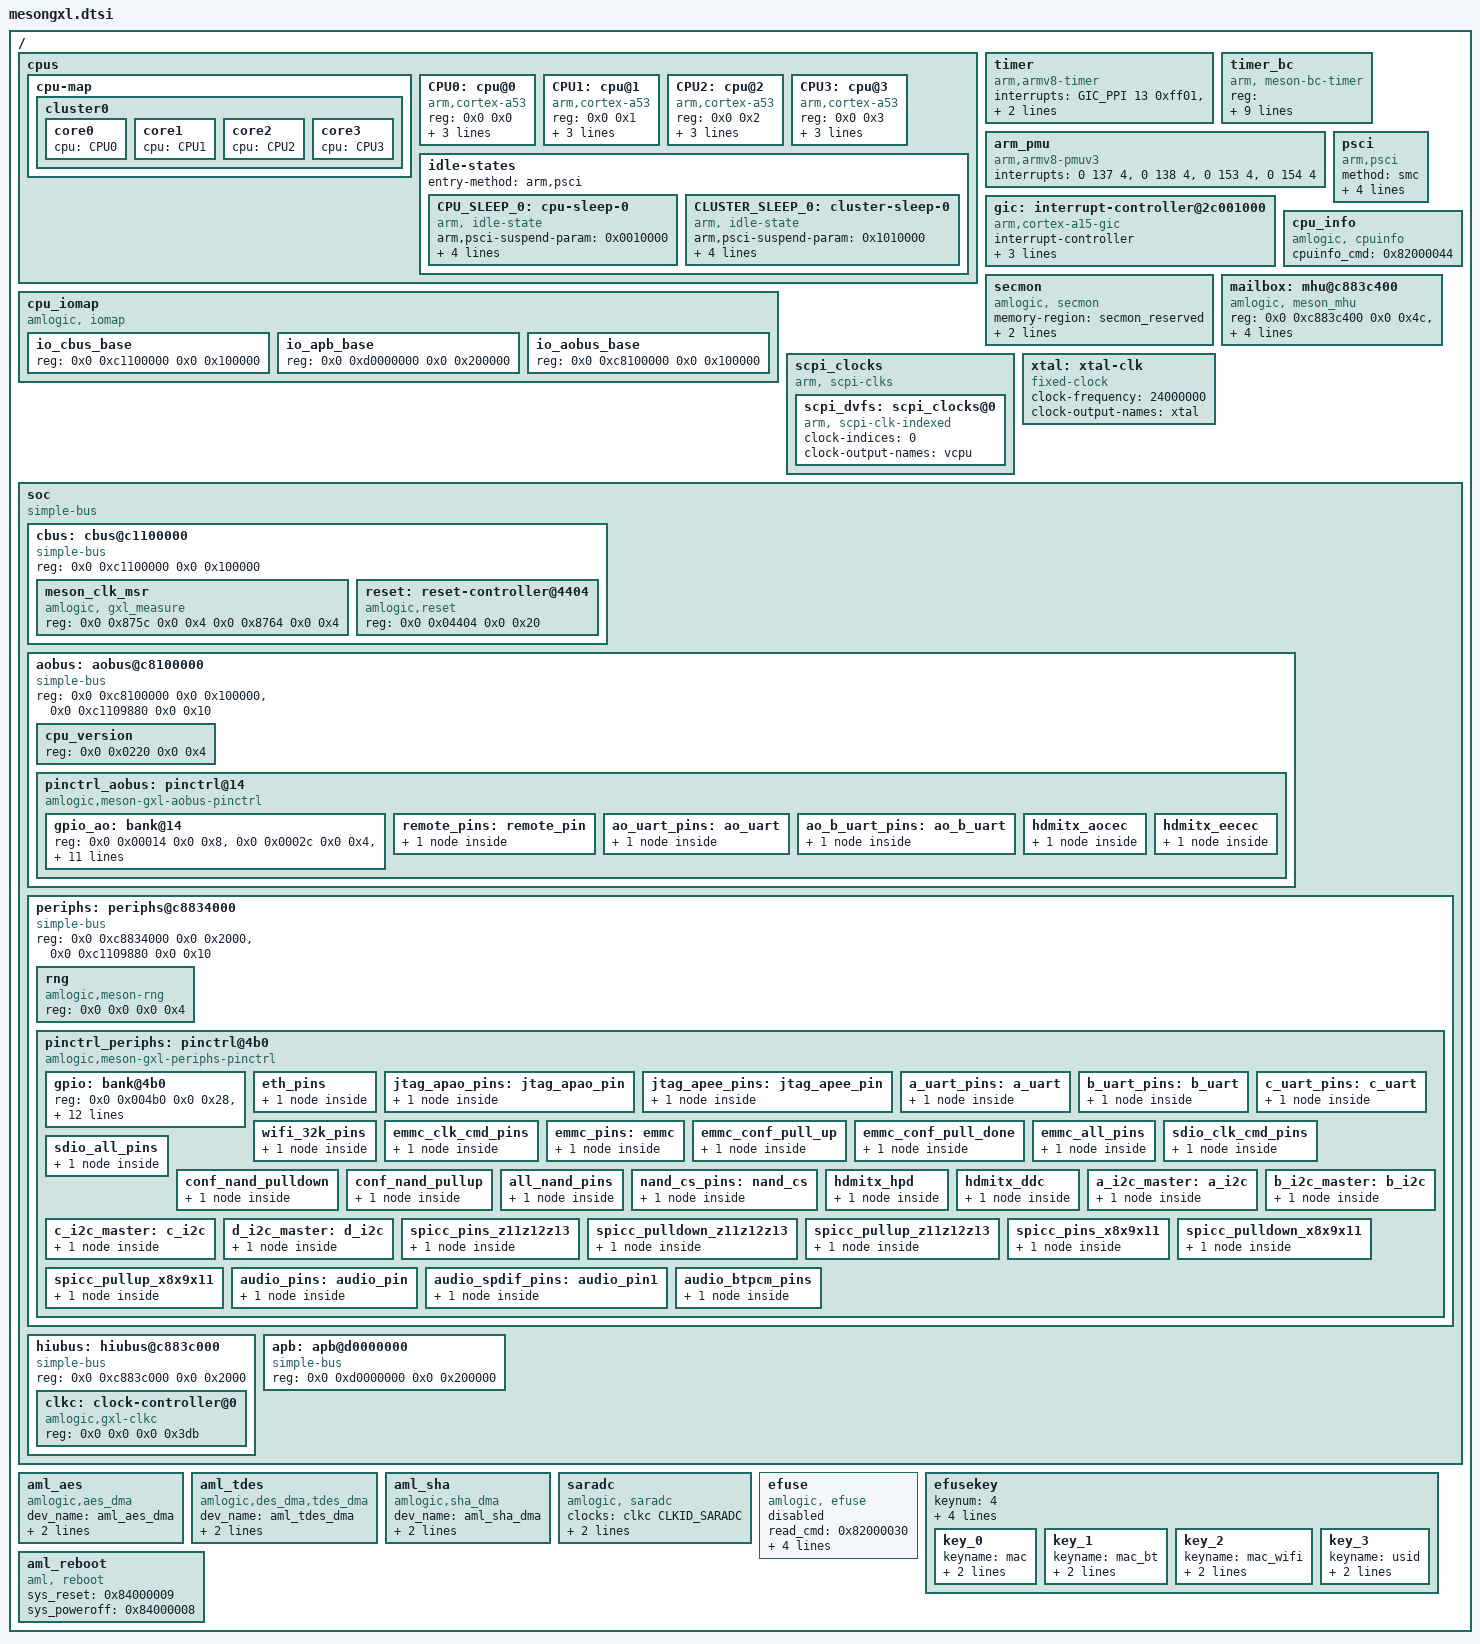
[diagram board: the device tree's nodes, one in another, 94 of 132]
/*
 * arch/arm64/boot/dts/amlogic/mesongxl.dtsi
 *
 * Copyright (C) 2017 Amlogic, Inc. All rights reserved.
 *
 * This program is free software; you can redistribute it and/or modify
 * it under the terms of the GNU General Public License as published by
 * the Free Software Foundation; either version 2 of the License, or
 * (at your option) any later version.
 *
 * This program is distributed in the hope that it will be useful, but WITHOUT
 * ANY WARRANTY; without even the implied warranty of MERCHANTABILITY or
 * FITNESS FOR A PARTICULAR PURPOSE.  See the GNU General Public License for
 * more details.
 *
 */

#include <dt-bindings/interrupt-controller/arm-gic.h>
#include <dt-bindings/reset/amlogic,gxl-reset.h>
#include <dt-bindings/clock/amlogic,gxl-clkc.h>
/ {
	cpus:cpus {
		#address-cells = <2>;
		#size-cells = <0>;

		cpu-map {
			cluster0:cluster0 {
				#cooling-cells = <2>; /* min followed by max */
				core0 {
					cpu = <&CPU0>;
				};
				core1 {
					cpu = <&CPU1>;
				};
				core2 {
					cpu = <&CPU2>;
				};
				core3 {
					cpu = <&CPU3>;
				};
			};
		};
		CPU0:cpu@0 {
			device_type = "cpu";
			compatible = "arm,cortex-a53","arm,armv8";
			reg = <0x0 0x0>;
			enable-method = "psci";
			clocks = <&scpi_dvfs 0>;
			clock-names = "cpu-cluster.0";
			cpu-idle-states = <&CPU_SLEEP_0 &CLUSTER_SLEEP_0>;
		};

		CPU1:cpu@1 {
			device_type = "cpu";
			compatible = "arm,cortex-a53","arm,armv8";
			reg = <0x0 0x1>;
			enable-method = "psci";
			clocks = <&scpi_dvfs 0>;
			clock-names = "cpu-cluster.0";
			cpu-idle-states = <&CPU_SLEEP_0 &CLUSTER_SLEEP_0>;
		};
		CPU2:cpu@2 {
			device_type = "cpu";
			compatible = "arm,cortex-a53","arm,armv8";
			reg = <0x0 0x2>;
			enable-method = "psci";
			clocks = <&scpi_dvfs 0>;
			clock-names = "cpu-cluster.0";
			cpu-idle-states = <&CPU_SLEEP_0 &CLUSTER_SLEEP_0>;
		};

		CPU3:cpu@3 {
			device_type = "cpu";
			compatible = "arm,cortex-a53","arm,armv8";
			reg = <0x0 0x3>;
			enable-method = "psci";
			clocks = <&scpi_dvfs 0>;
			clock-names = "cpu-cluster.0";
			cpu-idle-states = <&CPU_SLEEP_0 &CLUSTER_SLEEP_0>;
		};


		idle-states {
			entry-method = "arm,psci";

			CPU_SLEEP_0: cpu-sleep-0 {
				compatible = "arm, idle-state";
				arm,psci-suspend-param = <0x0010000>;
				local-timer-stop;
				entry-latency-us = <3000>;
				exit-latency-us = <3000>;
				min-residency-us = <8000>;
			};

			CLUSTER_SLEEP_0: cluster-sleep-0 {
				compatible = "arm, idle-state";
				arm,psci-suspend-param = <0x1010000>;
				local-timer-stop;
				entry-latency-us = <3000>;
				exit-latency-us = <3000>;
				min-residency-us = <15000>;
			};
		};
	};

	timer {
		compatible = "arm,armv8-timer";
		interrupts = <GIC_PPI 13 0xff01>,
				<GIC_PPI 14 0xff01>,
				<GIC_PPI 11 0xff01>,
				<GIC_PPI 10 0xff01>;
	};
	timer_bc {
		compatible = "arm, meson-bc-timer";
		reg=   <0x0 0xc1109990 0x0 0x4 0x0 0xc1109994 0x0 0x4>;
		timer_name = "Meson TimerF";
		clockevent-rating=<300>;
		clockevent-shift=<20>;
		clockevent-features=<0x23>;
		interrupts = <0 60 1>;
		bit_enable=<16>;
		bit_mode=<12>;
		bit_resolution=<0>;
	};
	arm_pmu {
		compatible = "arm,armv8-pmuv3";
		interrupts = <0 137 4>,
			     <0 138 4>,
			     <0 153 4>,
			     <0 154 4>;
	};

	gic: interrupt-controller@2c001000 {
		compatible = "arm,cortex-a15-gic", "arm,cortex-a9-gic";
		#interrupt-cells = <3>;
		#address-cells = <0>;
		interrupt-controller;
		reg = <0x0 0xc4301000 0 0x1000>,
		      <0x0 0xc4302000 0 0x0100>;
		interrupts = <GIC_PPI 9 0xf04>;
	};

	psci {
		compatible = "arm,psci";
		method = "smc";
		cpu_suspend = <0xC4000001>;
		cpu_off = <0x84000002>;
		cpu_on = <0xC4000003>;
		migrate = <0xC4000005>;
	};

	secmon {
		compatible = "amlogic, secmon";
		memory-region = <&secmon_reserved>;
		in_base_func = <0x82000020>;
		out_base_func = <0x82000021>;
	};

	cpu_iomap{
		compatible = "amlogic, iomap";
		#address-cells=<2>;
		#size-cells=<2>;
		ranges;
		io_cbus_base{
			reg = <0x0 0xc1100000 0x0 0x100000>;
		};
		io_apb_base{
			reg = <0x0 0xd0000000 0x0 0x200000>;
		};
		io_aobus_base{
			reg = <0x0 0xc8100000 0x0 0x100000>;
		};
	};

	cpu_info{
		compatible = "amlogic, cpuinfo";
		cpuinfo_cmd = <0x82000044>;
		status = "okay";
	};

	mailbox: mhu@c883c400 {
		compatible = "amlogic, meson_mhu";
		reg = <0x0 0xc883c400 0x0 0x4c>,   /* MHU registers */
		      <0x0 0xc8013000 0x0 0x800>;   /* Payload area */
		interrupts = <0 209 1>,   /* low priority interrupt */
			     <0 210 1>;   /* high priority interrupt */
		#mbox-cells = <1>;
		mbox-names = "cpu_to_scp_low", "cpu_to_scp_high";
		mboxes = <&mailbox 0 &mailbox 1>;
	};

	scpi_clocks {
		compatible = "arm, scpi-clks";

		scpi_dvfs: scpi_clocks@0 {
			compatible = "arm, scpi-clk-indexed";
			#clock-cells = <1>;
			clock-indices = <0>;
			clock-output-names = "vcpu";
		};

	};

	xtal: xtal-clk {
		compatible = "fixed-clock";
		clock-frequency = <24000000>;
		clock-output-names = "xtal";
		#clock-cells = <0>;
	};

	soc {
		compatible = "simple-bus";
		#address-cells = <2>;
		#size-cells = <2>;
		ranges;

		cbus: cbus@c1100000 {
			compatible = "simple-bus";
			reg = <0x0 0xc1100000 0x0 0x100000>;
			#address-cells = <2>;
			#size-cells = <2>;
			ranges = <0x0 0x0 0x0 0xc1100000 0x0 0x100000>;

			meson_clk_msr{
				compatible = "amlogic, gxl_measure";
				reg = <0x0 0x875c 0x0 0x4
					0x0 0x8764 0x0 0x4>;
			};
		};

		aobus: aobus@c8100000 {
			compatible = "simple-bus";
			reg = <0x0 0xc8100000 0x0 0x100000>,
				<0x0 0xc1109880 0x0 0x10>;
			#address-cells = <2>;
			#size-cells = <2>;
			ranges = <0x0 0x0 0x0 0xc8100000 0x0 0x100000>;

			cpu_version{
				reg=<0x0 0x0220 0x0 0x4>;
			};
		};

		periphs: periphs@c8834000 {
			compatible = "simple-bus";
			reg = <0x0 0xc8834000 0x0 0x2000>,
				<0x0 0xc1109880 0x0 0x10>;
			#address-cells = <2>;
			#size-cells = <2>;
			ranges = <0x0 0x0 0x0 0xc8834000 0x0 0x2000>;
		};

		hiubus: hiubus@c883c000 {
			compatible = "simple-bus";
			reg = <0x0 0xc883c000 0x0 0x2000>;
			#address-cells = <2>;
			#size-cells = <2>;
			ranges = <0x0 0x0 0x0 0xc883c000 0x0 0x2000>;

			clkc: clock-controller@0 {
				compatible = "amlogic,gxl-clkc";
				#clock-cells = <1>;
				reg = <0x0 0x0 0x0 0x3db>;
			};
		};

		apb: apb@d0000000 {
			compatible = "simple-bus";
			reg = <0x0 0xd0000000 0x0 0x200000>;
			#address-cells = <2>;
			#size-cells = <2>;
			ranges = <0x0 0x0 0x0 0xd0000000 0x0 0x200000>;
		};
	}; /* end of soc */
}; /* end of root */

&aobus {
	pinctrl_aobus: pinctrl@14 {
		compatible = "amlogic,meson-gxl-aobus-pinctrl";
		#address-cells = <2>;
		#size-cells = <2>;
		ranges;

		gpio_ao: bank@14 {
			reg = <0x0 0x00014 0x0 0x8>,
			      <0x0 0x0002c 0x0 0x4>,
			      <0x0 0x00024 0x0 0x8>;
			interrupts = <GIC_SPI 64 IRQ_TYPE_EDGE_RISING>,
				<GIC_SPI 65 IRQ_TYPE_EDGE_RISING>,
				<GIC_SPI 66 IRQ_TYPE_EDGE_RISING>,
				<GIC_SPI 67 IRQ_TYPE_EDGE_RISING>,
				<GIC_SPI 68 IRQ_TYPE_EDGE_RISING>,
				<GIC_SPI 69 IRQ_TYPE_EDGE_RISING>,
				<GIC_SPI 70 IRQ_TYPE_EDGE_RISING>,
				<GIC_SPI 71 IRQ_TYPE_EDGE_RISING>;
			reg-names = "mux", "pull", "gpio";
			gpio-controller;
			#gpio-cells = <2>;
			interrupt-controller;
			#interrupt-cells = <2>;
		};

		remote_pins:remote_pin {
			mux {
				groups = "remote_input";
				function = "remote";
			};
		};

		ao_uart_pins:ao_uart {
			mux {
				groups = "uart_tx_ao_a_0",
					"uart_rx_ao_a_0";
				function = "uart_ao";
			};
		};

		ao_b_uart_pins:ao_b_uart {
			mux {
				groups = "uart_tx_ao_b_0",
						"uart_rx_ao_b_0";
				function = "uart_ao_b";
			};
		};

		hdmitx_aocec: hdmitx_aocec {
			mux {
				groups = "ao_cec";
				function = "ao_cec";
			};
		};

		hdmitx_eecec: hdmitx_eecec {
			mux {
				groups = "ee_cec";
				function = "ee_cec";
			};
		};
	}; /* end of pinctrl_aobus*/

}; /* end of aobus*/

&periphs {
	rng {
		compatible = "amlogic,meson-rng";
		reg = <0x0 0x0 0x0 0x4>;
	};

	pinctrl_periphs: pinctrl@4b0 {
		compatible = "amlogic,meson-gxl-periphs-pinctrl";
		#address-cells = <2>;
		#size-cells = <2>;
		ranges;

		gpio: bank@4b0 {
			reg = <0x0 0x004b0 0x0 0x28>,
			      <0x0 0x004e8 0x0 0x14>,
			      <0x0 0x00120 0x0 0x14>,
			      <0x0 0x00430 0x0 0x40>;
			interrupts = <GIC_SPI 64 IRQ_TYPE_EDGE_RISING>,
				<GIC_SPI 65 IRQ_TYPE_EDGE_RISING>,
				<GIC_SPI 66 IRQ_TYPE_EDGE_RISING>,
				<GIC_SPI 67 IRQ_TYPE_EDGE_RISING>,
				<GIC_SPI 68 IRQ_TYPE_EDGE_RISING>,
				<GIC_SPI 69 IRQ_TYPE_EDGE_RISING>,
				<GIC_SPI 70 IRQ_TYPE_EDGE_RISING>,
				<GIC_SPI 71 IRQ_TYPE_EDGE_RISING>;
			reg-names = "mux", "pull",
				"pull-enable", "gpio";
			gpio-controller;
			#gpio-cells = <2>;
			interrupt-controller;
			#interrupt-cells = <2>;
		};

		eth_pins:eth_pins {
			mux {
				groups = "eth_mdio",
					"eth_mdc",
					"eth_clk_rx_clk",
					"eth_rx_dv",
					"eth_rxd0",
					"eth_rxd1",
					"eth_rxd2",
					"eth_rxd3",
					"eth_rgmii_tx_clk",
					"eth_tx_en",
					"eth_txd0",
					"eth_txd1",
					"eth_txd2",
					"eth_txd3";
				function = "eth";
			};
		};

		jtag_apao_pins:jtag_apao_pin {
			mux {
				groups = "jtag_tdi_0",
					"jtag_tdo_0",
					"jtag_clk_0",
					"jtag_tms_0";
				function = "jtag";
			};
		};

		jtag_apee_pins:jtag_apee_pin {
			mux {
				groups ="jtag_tdi_1",
					"jtag_tdo_1",
					"jtag_clk_1",
					"jtag_tms_1";
				function = "jtag";
			};
		};

		a_uart_pins:a_uart {
			mux {
				groups = "uart_tx_a",
					"uart_rx_a";
				function = "uart_a";
			};
		};

		b_uart_pins:b_uart {
			mux {
				groups = "uart_tx_b",
					"uart_rx_b";
				function = "uart_b";
			};
		};

		c_uart_pins:c_uart {
			mux {
				groups = "uart_tx_c",
					"uart_rx_c";
				function = "uart_c";
			};
		};

		wifi_32k_pins:wifi_32k_pins {
			mux {
				groups ="pwm_e";
				function = "pwm_e";
			};
		};

/*
 * sd_clk_cmd_pins:sd_clk_cmd_pins{
 * };
 * sd_all_pins:sd_all_pins {
 *  };
 * sd_1bit_pins:sd_1bit_pins{
 *  };
 *  sd_clk_cmd_uart_pins:sd_clk_cmd_uart_pins {
 * };
 * sd_1bit_uart_pins:sd_1bit_uart_pins {
 *  };
 * sd_to_ao_uart_pins:sd_to_ao_uart_pins {
 *  };
 * ao_to_sd_uart_pins:ao_to_sd_uart_pins {
 * };
 * sd_to_ao_jtag_pins:sd_to_ao_jtag_pins{
 * };
 */

		emmc_clk_cmd_pins:emmc_clk_cmd_pins {
			mux {
				groups = "emmc_cmd",
					"emmc_clk";
				function = "emmc";
				bias-pull-up;
				input-enable;
			};
		};

		emmc_pins: emmc {
			mux {
				groups = "emmc_nand_d07",
					"emmc_cmd",
					"emmc_clk";
				function = "emmc";
			};
		};

		emmc_conf_pull_up:emmc_conf_pull_up {
			mux {
				groups = "emmc_nand_d07",
					"emmc_clk",
					"emmc_cmd";
				function = "emmc";
				bias-pull-up;
			};
		};

		emmc_conf_pull_done:emmc_conf_pull_done {
			mux {
				groups = "emmc_ds";
				function = "emmc";
				bias-pull-down;
			};
		};

		emmc_all_pins:emmc_all_pins {
			mux {
				groups = "emmc_nand_d07",
					"emmc_clk",
					"emmc_cmd";
				function = "emmc";
				input-enable;
			};
		};

		sdio_clk_cmd_pins:sdio_clk_cmd_pins {
			mux {
				groups = "sdio_clk",
					"sdio_cmd";
				function = "sdio";
				input-enable;
				bias-pull-up;
			};
		};

		sdio_all_pins:sdio_all_pins {
			mux {
				groups = "sdio_d0",
					"sdio_d1",
					"sdio_d2",
					"sdio_d3",
					"sdio_clk",
					"sdio_cmd";
				function = "sdio";
				input-enable;
				bias-pull-up;
			};
		};

		conf_nand_pulldown: conf_nand_pulldown {
			mux {
				groups = "emmc_nand_d07",
					"emmc_ds";
				function = "emmc";
				bias-pull-down;
			};
		};

		conf_nand_pullup: conf_nand_pullup {
			mux {
				groups = "emmc_clk",
					"emmc_cmd";
				function = "emmc";
				bias-pull-up;
			};
		};

		all_nand_pins: all_nand_pins {
			mux {
				groups = "emmc_nand_d07",
					"nand_ce0",
					"nand_ce1",
					"nand_rb0",
					"nand_ale",
					"nand_cle",
					"nand_wen_clk",
					"nand_ren_wr",
					"nand_dqs";
				function = "nand";
				input-enable;
			};
		};

		nand_cs_pins: nand_cs {
			mux {
				groups = "nand_ce0",
					"nand_ce1";
				function = "nand";
			};
		};

		hdmitx_hpd: hdmitx_hpd {
			mux {
				groups = "hdmi_hpd";
				function = "hdmi_hpd";
			};
		};

		hdmitx_ddc: hdmitx_ddc {
			mux {
				groups = "hdmi_sda",
					"hdmi_scl";
				function = "hdmi_ddc";
			};
		};

		a_i2c_master:a_i2c {
			mux {
				groups = "i2c_sda_a",
					"i2c_sda_a";
				function = "i2c_a";
			};
		};

		b_i2c_master:b_i2c {
			mux {
				groups = "i2c_sda_b",
					"i2c_sda_b";
				function = "i2c_b";
			};
		};

		c_i2c_master:c_i2c {
			mux {
				groups = "i2c_sda_c",
					"i2c_sda_c";
				function = "i2c_c";
			};
		};

		d_i2c_master:d_i2c {
			mux {
			groups = "i2c_sda_d",
				"i2c_sda_d";
			function = "i2c_d";
			};
		};

		spicc_pins_z11z12z13: spicc_pins_z11z12z13 {
			mux {
				groups = "spi_sclk_0",
					"spi_miso_0",
					"spi_mosi_0";
				function = "spi";
			};
		};

		spicc_pulldown_z11z12z13: spicc_pulldown_z11z12z13 {
			mux {
				groups = "spi_sclk_0",
					"spi_miso_0",
					"spi_mosi_0";
				function = "spi";
			};
		};

		spicc_pullup_z11z12z13: spicc_pullup_z11z12z13 {
			mux {
				groups = "spi_sclk_0",
					"spi_miso_0",
					"spi_mosi_0";
				function = "spi";
			};
		};

		spicc_pins_x8x9x11: spicc_pins_x8x9x11 {
			mux {
				groups = "spi_sclk_1",
					"spi_miso_1",
					"spi_mosi_1";
				function = "spi";
			};
		};

		spicc_pulldown_x8x9x11: spicc_pulldown_x8x9x11 {
			mux {
				groups = "spi_sclk_1",
					"spi_miso_1",
					"spi_mosi_1";
				function = "spi";
				bias-pull-down;
			};
		};

		spicc_pullup_x8x9x11: spicc_pullup_x8x9x11 {
			mux {
				groups = "spi_sclk_1",
					"spi_miso_1",
					"spi_mosi_1";
				function = "spi";
				bias-pull-up;
			};
		};

		audio_pins:audio_pin {
			mux {
				groups = "i2s_am_clk",
					"i2s_ao_clk_out",
					"i2s_lr_clk_out",
					"i2sout_ch01";
				function = "i2s";
			};
		};

		audio_spdif_pins:audio_pin1 {
			mux {
				groups = "spdif_out";
				function = "spdif_out";
			};
		};

		audio_btpcm_pins:audio_btpcm_pins {
			mux {
				groups = "pcm_out_a",
					"pcm_in_a",
					"pcm_fs_a",
					"pcm_clk_a";
				function = "pcm_a";
			};
		};
	}; /* end of pinctrl_periphs */
}; /* end of periphs */

&cbus{
	reset: reset-controller@4404 {
		compatible = "amlogic,reset";
		reg = <0x0 0x04404 0x0 0x20>;
		#reset-cells = <1>;
	};
};

/{
	aml_aes {
		compatible = "amlogic,aes_dma";
		dev_name = "aml_aes_dma";
		status = "okay";
		interrupts = <0 188 1 0 189 1>;
		reg = <0x0 0xc883e000 0x0 0x28>;
	};

	aml_tdes {
		compatible = "amlogic,des_dma,tdes_dma";
		dev_name = "aml_tdes_dma";
		status = "okay";
		interrupts = <0 188 1 0 189 1>;
		reg = <0x0 0xc883e000 0x0 0x28>;
	};

	aml_sha {
		compatible = "amlogic,sha_dma";
		dev_name = "aml_sha_dma";
		status = "okay";
		interrupts = <0 188 1 0 189 1>;
		reg = <0x0 0xc883e000 0x0 0x28>;
	};

	saradc: saradc {
		compatible = "amlogic, saradc";
		status = "okay";
		clocks = <&clkc CLKID_SARADC>;
		clock-names = "saradc_clk";
		reg = <0x0 0xc1108680 0x0 0x30
		       0x0 0xc883c3d8 0x0 0x08>;
	};

	efuse: efuse{
		compatible = "amlogic, efuse";
		read_cmd = <0x82000030>;
		write_cmd = <0x82000031>;
		get_max_cmd = <0x82000033>;
		key = <&efusekey>;
		clocks = <&clkc CLKID_EFUSE>;
		clock-names = "efuse_clk";
		status = "disabled";
	};

	efusekey:efusekey{
		keynum = <4>;
		key0 = <&key_0>;
		key1 = <&key_1>;
		key2 = <&key_2>;
		key3 = <&key_3>;
		key_0:key_0{
			keyname = "mac";
			offset = <0>;
			size = <6>;
		};
		key_1:key_1{
			keyname = "mac_bt";
			offset = <6>;
			size = <6>;
		};
		key_2:key_2{
			keyname = "mac_wifi";
			offset = <12>;
			size = <6>;
		};
		key_3:key_3{
			keyname = "usid";
			offset = <18>;
			size = <16>;
		};
	};

	aml_reboot {
		compatible = "aml, reboot";
		sys_reset = <0x84000009>;
		sys_poweroff = <0x84000008>;
	};
};

